# nrf9230_radiocore register map
Vendor: Nordic Semiconductor; Series: nRF92; File version: 1
CPU: CM33 r0p4, little endian, MPU, FPU, 3 interrupt priority bits, 480 interrupts, 8 SAU regions
Registers are 32-bit, read-write, reset 0x0 unless marked. A register's access mark holds for its fields unless they carry their own. Offsets are from the block's base; [hi:lo] are bit positions; lines under a group give offsets from that group; {n}, {i} and the like mark numbered series; 'fields as' and 'values as' point back to an identical list.

## RESETINFO_S — RESETINFO
Base 0x5301E000; alternate view of LRCCONF010_S
0x4A0 RESETREAS group — Unspecified
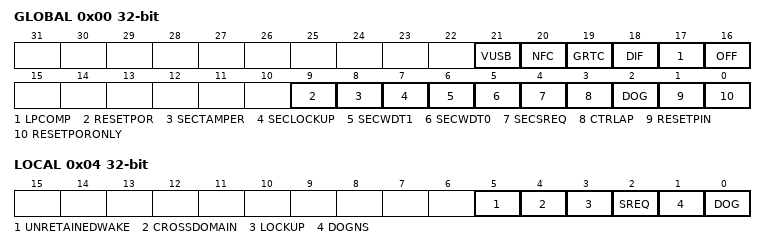
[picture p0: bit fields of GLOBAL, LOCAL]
  0x00 GLOBAL — Global reset reason.
    [all] fields
      0=NotDetected; 1=Detected
    [21] VUSB — Reset after wakeup from System OFF mode due to VBUS rising into valid range.
    [20] NFC — Reset due to wakeup from System OFF mode when wakeup is triggered by NFC field detection in sense mode.
    [19] GRTC — Reset due to wakeup from System OFF mode when wakeup is triggered by GRTC interrupt.
    [18] DIF — Reset due to wakeup from System OFF mode when wakeup is triggered by entering the debug interface mode.
    [17] LPCOMP — Reset due to wakeup from System OFF mode when wakeup is triggered by LPCOMP (Low Power Comparator).
    [16] OFF — Reset due to wakeup from System OFF mode when wakeup is triggered by DETECT signal from GPIO.
    [9] RESETPOR — Reset from power on reset (reset reason other than POR or BOR).
    [8] SECTAMPER — Reset due to secure domain tamper detected
    [7] SECLOCKUP — Reset due to secure domain lockup.
    [6] SECWDT1 — Reset due to the second instance of watchdog timer in secure domain detected.
    [5] SECWDT0 — Reset due to the first instance of watchdog timer in secure domain detected.
    [4] SECSREQ — Reset due to secure domain system reset request.
    [3] CTRLAP — Reset from CTRL-AP detected.
    [2] DOG — Reset from the SysCtrl watchdog timer detected.
    [1] RESETPIN — Reset from pin reset detected.
    [0] RESETPORONLY — Reset from power on reset (reset reason POR or BOR).
  0x04 LOCAL — Local reset reason.
    [5] UNRETAINEDWAKE — Reset due to wake from unretained state.
    [4] CROSSDOMAIN — Reset due to cross domain reset source.
      0=NotDetected; 1=Detected
    [3] LOCKUP — Reset from local CPU lockup detected
      0=NotDetected; 1=Detected
    [2] SREQ — Reset from the local soft reset request detected.
      0=NotDetected; 1=Detected
    [1] DOGNS — Reset from the local non-secure watchdog timer detected
      0=NotDetected; 1=Detected
    [0] DOG — Reset from the local watchdog timer detected
      0=NotDetected; 1=Detected
0x4A8 ERROR group — Unspecified
  0x00 STATUS — Reset error status.
    [3:0] ERRORSTATUS
  0x04 ADDRESS — Reset error address.
    [31:0] ERRORADDRESS
0x4C0 RESTOREVALID — Valid restore image is present in RAM.
  [0] RESTOREVALID
    0=NotPreset (Not present); 1=Present
0x4C4 MASKLOCKUP — Mask CPU lockup signal.
  [0] MASK — Mask lockup signal
    0=NotMask (Do not mask lockup signal); 1=Mask lockup signal

## DPPIC020_NS — Distributed programmable peripheral interconnect controller 0
Base 0x43022000
Same registers: DPPIC030_NS 0x43032000, GLOBAL_DPPIC120_NS 0x4F8E1000, GLOBAL_DPPIC130_NS 0x4F922000, GLOBAL_DPPIC131_NS 0x4F981000, GLOBAL_DPPIC132_NS 0x4F991000, GLOBAL_DPPIC133_NS 0x4F9A1000, GLOBAL_DPPIC134_NS 0x4F9B1000, GLOBAL_DPPIC135_NS 0x4F9C1000, GLOBAL_DPPIC136_NS 0x4F9D1000, DPPIC020_S 0x53022000, DPPIC030_S 0x53032000, GLOBAL_DPPIC120_S 0x5F8E1000, GLOBAL_DPPIC130_S 0x5F922000, GLOBAL_DPPIC131_S 0x5F981000, GLOBAL_DPPIC132_S 0x5F991000, GLOBAL_DPPIC133_S 0x5F9A1000, GLOBAL_DPPIC134_S 0x5F9B1000, GLOBAL_DPPIC135_S 0x5F9C1000, GLOBAL_DPPIC136_S 0x5F9D1000
{0x0+8i} TASKS_CHG[{i}] (i=0..3) group — Channel group tasks
  0x00 EN wo — Description cluster: Enable channel group n
    [0] EN — Enable channel group n
      1=Trigger task
  0x04 DIS wo — Description cluster: Disable channel group n
    [0] DIS — Disable channel group n
      1=Trigger task
{0x80+8i} SUBSCRIBE_CHG[{i}] (i=0..3) group — Subscribe configuration for tasks
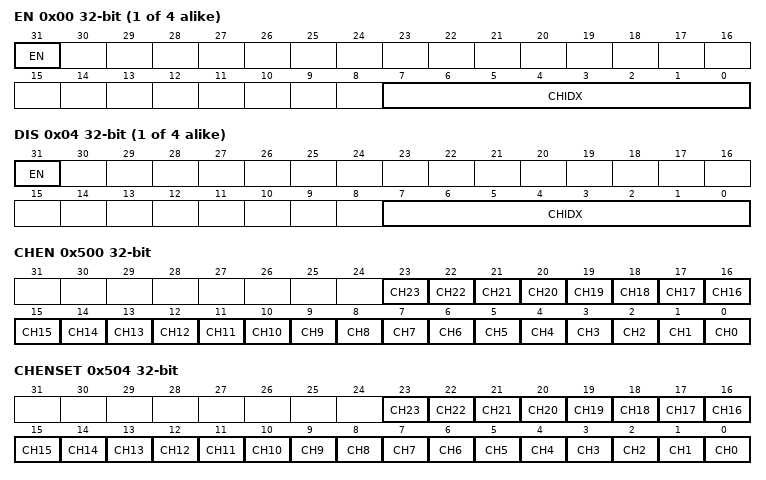
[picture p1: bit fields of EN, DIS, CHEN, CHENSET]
  0x00 EN — Description cluster: Subscribe configuration for task CHG[n].EN
    [31] EN
      0=Disabled (Disable subscription); 1=Enabled (Enable subscription)
    [7:0] CHIDX — DPPI channel that task CHG[n].EN will subscribe to
  0x04 DIS — Description cluster: Subscribe configuration for task CHG[n].DIS
    [31] EN
      values as SUBSCRIBE_CHG[0].EN.EN
    [7:0] CHIDX — DPPI channel that task CHG[n].DIS will subscribe to
0x500 CHEN — Channel enable register
  [all] fields
    0=Disabled (Disable channel); 1=Enabled (Enable channel)
  [n] CH{n} (n=0..23) — Enable or disable channel {n}
0x504 CHENSET write-1-sets — Channel enable set register
  [all] fields
    on read: 0=Disabled (Read: Channel disabled); 1=Enabled (Read: Channel enabled) | on write: 1=Set (Write: Enable channel)
  [n] CH{n} (n=0..23) — Channel {n} enable set register. Writing 0 has no effect.
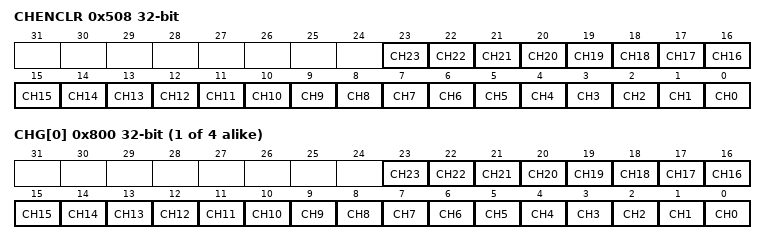
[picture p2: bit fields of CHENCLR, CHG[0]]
0x508 CHENCLR write-1-clears — Channel enable clear register
  [all] fields
    on read: 0=Disabled (Read: Channel disabled); 1=Enabled (Read: Channel enabled) | on write: 1=Clear (Write: Disable channel)
  [n] CH{n} (n=0..23) — Channel {n} enable clear register. Writing 0 has no effect.
{0x800+4i} CHG[{i}] (i=0..3) — Description collection: Channel group n Note: Writes to this register are ignored if either SUBSCRIBE_CHG[n].EN or SUBSCRIBE_CHG[n].DIS is enabled
  [all] fields
    0=Excluded; 1=Included
  [n] CH{n} (n=0..23) — Include or exclude channel {n}

## Notices in the file
Copyright (c) 2010 - 2024, Nordic Semiconductor ASA
All rights reserved.
Redistribution and use in source and binary forms, with or without modification,
are permitted provided that the following conditions are met:
1. Redistributions of source code must retain the above copyright notice, this
list of conditions and the following disclaimer.
2. Redistributions in binary form, except as embedded into a Nordic
Semiconductor ASA integrated circuit in a product or a software update for
such product, must reproduce the above copyright notice, this list of
conditions and the following disclaimer in the documentation and/or other
materials provided with the distribution.
3. Neither the name of Nordic Semiconductor ASA nor the names of its
contributors may be used to endorse or promote products derived from this
software without specific prior written permission.
4. This software, with or without modification, must only be used with a
Nordic Semiconductor ASA integrated circuit.
5. Any software provided in binary form under this license must not be reverse
engineered, decompiled, modified and/or disassembled.
THIS SOFTWARE IS PROVIDED BY NORDIC SEMICONDUCTOR ASA "AS IS" AND ANY EXPRESS
OR IMPLIED WARRANTIES, INCLUDING, BUT NOT LIMITED TO, THE IMPLIED WARRANTIES
OF MERCHANTABILITY, NONINFRINGEMENT, AND FITNESS FOR A PARTICULAR PURPOSE ARE
DISCLAIMED. IN NO EVENT SHALL NORDIC SEMICONDUCTOR ASA OR CONTRIBUTORS BE
LIABLE FOR ANY DIRECT, INDIRECT, INCIDENTAL, SPECIAL, EXEMPLARY, OR
CONSEQUENTIAL DAMAGES (INCLUDING, BUT NOT LIMITED TO, PROCUREMENT OF SUBSTITUTE
GOODS OR SERVICES; LOSS OF USE, DATA, OR PROFITS; OR BUSINESS INTERRUPTION)
HOWEVER CAUSED AND ON ANY THEORY OF LIABILITY, WHETHER IN CONTRACT, STRICT
LIABILITY, OR TORT (INCLUDING NEGLIGENCE OR OTHERWISE) ARISING IN ANY WAY OUT
OF THE USE OF THIS SOFTWARE, EVEN IF ADVISED OF THE POSSIBILITY OF SUCH DAMAGE.
